# AT90PWM316 device description
Architecture: AVR8; Family: megaAVR
Registers are 8-bit, access not given, no defined reset value unless marked. A register's access mark holds for its fields unless they carry their own. Offsets are from the block's base; [hi:lo] are bit positions; {n}, {i} and the like mark numbered series.

## ADC — Analog-to-Digital Converter
Instances: ADC 0x00
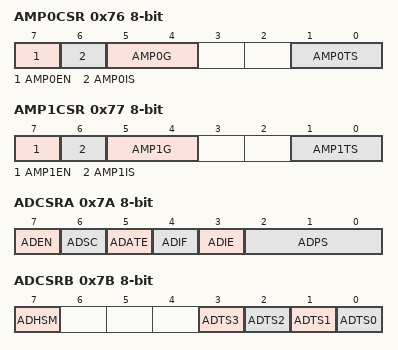
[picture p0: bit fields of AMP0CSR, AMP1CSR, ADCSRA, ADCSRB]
0x76 AMP0CSR
  [7] AMP0EN, [6] AMP0IS, [5:4] AMP0G, [1:0] AMP0TS
0x77 AMP1CSR
  [7] AMP1EN, [6] AMP1IS, [5:4] AMP1G, [1:0] AMP1TS
0x78 ADC 16-bit — ADC Data Register Bytes
0x7A ADCSRA — The ADC Control and Status register
  [7] ADEN — ADC Enable
  [6] ADSC — ADC Start Conversion
  [5] ADATE — ADC Auto Trigger Enable
  [4] ADIF — ADC Interrupt Flag
  [3] ADIE — ADC Interrupt Enable
  [2:0] ADPS — ADC Prescaler Select Bits
0x7B ADCSRB — ADC Control and Status Register B
  [7] ADHSM — ADC High Speed Mode
  [n] ADTS{n} (n=0..3) — ADC Auto Trigger Source Selection {n}
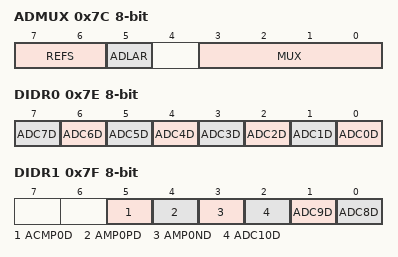
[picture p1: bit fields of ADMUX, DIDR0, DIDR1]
0x7C ADMUX — The ADC multiplexer Selection Register
  [7:6] REFS — Reference Selection Bits
    0=AREF, Internal Vref turned off; 1=AVCC with external capacitor at AREF pin; 3=Internal 2.56V Voltage Reference with external capacitor at AREF pin
  [5] ADLAR — Left Adjust Result
  [3:0] MUX — Analog Channel and Gain Selection Bits
0x7E DIDR0 — Digital Input Disable Register 0
  [n] ADC{n}D (n=0..7)
0x7F DIDR1 — Digital Input Disable Register 1
  [5] ACMP0D, [4] AMP0PD, [3] AMP0ND, [2] ADC10D, [1] ADC9D, [0] ADC8D

## USART
Instances: USART 0x00
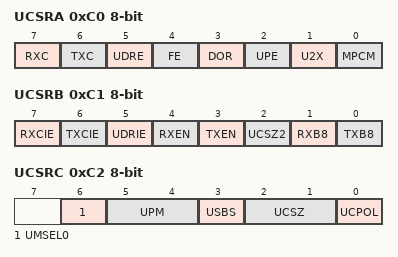
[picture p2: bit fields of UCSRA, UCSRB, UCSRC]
0xC0 UCSRA — USART Control and Status register A
  [7] RXC — USART Receive Complete
  [6] TXC — USART Transmitt Complete
  [5] UDRE — USART Data Register Empty
  [4] FE — Framing Error
  [3] DOR — Data Overrun
  [2] UPE — USART Parity Error
  [1] U2X — Double USART Transmission Bit
  [0] MPCM — Multi-processor Communication Mode
0xC1 UCSRB — USART Control an Status register B
  [7] RXCIE — RX Complete Interrupt Enable
  [6] TXCIE — TX Complete Interrupt Enable
  [5] UDRIE — USART Data Register Empty Interrupt Enable
  [4] RXEN — Receiver Enable
  [3] TXEN — Transmitter Enable
  [2] UCSZ2 — Character Size
  [1] RXB8 — Receive Data Bit 8
  [0] TXB8 — Transmit Data Bit 8
0xC2 UCSRC — USART Control an Status register C
  [6] UMSEL0 — USART Mode Select
  [5:4] UPM — Parity Mode Bits
    0=Disabled; 2=Enabled, Even Parity; 3=Enabled, Odd Parity
  [3] USBS — Stop Bit Select
    0=1-bit; 1=2-bit
  [2:1] UCSZ — Character Size Bits
  [0] UCPOL — Clock Polarity
0xC4 UBRRL — USART Baud Rate Register Low Byte
  [7:0] UBRR — USART Baud Rate Register bits
0xC5 UBRRH — USART Baud Rate Register High Byte
  [3:0] UBRR (bit 8 of the value upward) — USART Baud Rate Register Bits
0xC6 UDR — USART I/O Data Register

## SPI — Serial Peripheral Interface
Instances: SPI 0x00
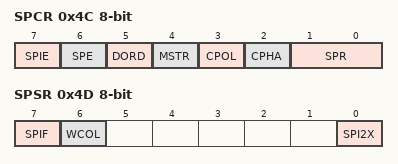
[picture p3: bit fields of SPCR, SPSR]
0x4C SPCR — SPI Control Register
  [7] SPIE — SPI Interrupt Enable
  [6] SPE — SPI Enable
  [5] DORD — Data Order
  [4] MSTR — Master/Slave Select
  [3] CPOL — Clock polarity
  [2] CPHA — Clock Phase
  [1:0] SPR — SPI Clock Rate Selects
    0=fosc/4; 1=fosc/16; 2=fosc/64; 3=fosc/128; 4=fosc/2; 5=fosc/8; 6=fosc/32; 7=fosc/64
0x4D SPSR — SPI Status Register
  [7] SPIF — SPI Interrupt Flag
  [6] WCOL — Write Collision Flag
  [0] SPI2X — Double SPI Speed Bit
0x4E SPDR — SPI Data Register
  [7:0] SPD — SPI Data

## WDT — Watchdog Timer
Instances: WDT 0x00
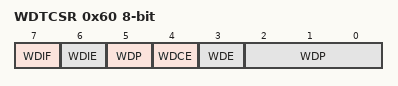
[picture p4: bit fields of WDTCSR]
0x60 WDTCSR — Watchdog Timer Control Register
  [7] WDIF — Watchdog Timeout Interrupt Flag
  [6] WDIE — Watchdog Timeout Interrupt Enable
  [4] WDCE — Watchdog Change Enable
  [3] WDE — Watch Dog Enable
  [5,2:0] WDP — Watchdog Timer Prescaler Bits
    0=Oscillator Cycles 2K; 1=Oscillator Cycles 4K; 2=Oscillator Cycles 8K; 3=Oscillator Cycles 16K; 4=Oscillator Cycles 32K; 5=Oscillator Cycles 64K; 6=Oscillator Cycles 128K; 7=Oscillator Cycles 256K; 8=Oscillator Cycles 512K; 9=Oscillator Cycles 1024K

## EXINT — External Interrupts
Instances: EXINT 0x00
0x3C EIFR — External Interrupt Flag Register
  [3:0] INTF — External Interrupt Flags
0x3D EIMSK — External Interrupt Mask Register
  [3:0] INT — External Interrupt Request 3 Enable
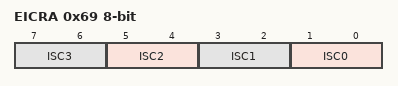
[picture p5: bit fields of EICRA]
0x69 EICRA — External Interrupt Control Register A
  [all] fields
    0=Low Level of INTX; 1=Any Logical Change of INTX; 2=Falling Edge of INTX; 3=Rising Edge of INTX
  [2n+1:2n] ISC{n} (n=0..3) — External Interrupt Sense Control Bit
